# MIMXRT685S_cm33 register map
Vendor: nxp.com; File version: 1.0
CPU: CM33 r2p0, little endian, MPU, FPU, VTOR, 3 interrupt priority bits
Registers are 32-bit, read-write, reset 0x0 unless marked. A register's access mark holds for its fields unless they carry their own. Offsets are from the block's base; [hi:lo] are bit positions; lines under a group give offsets from that group; {n}, {i} and the like mark numbered series; 'fields as' and 'values as' point back to an identical list.

## OTFAD
Base 0x40134000; alternate view of FLEXSPI
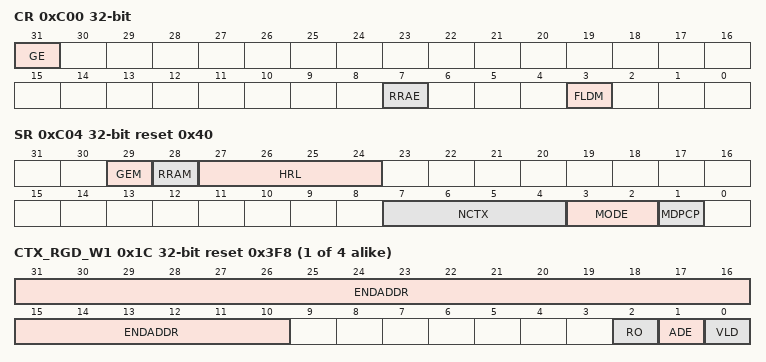
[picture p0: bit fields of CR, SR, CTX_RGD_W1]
0xC00 CR — Control Register
  [31] GE — Global OTFAD Enable
    0=OTFAD has decryption disabled. All data fetched by the FLEXSPI bypasses OTFAD processing.; 1=OTFAD has decryption enabled, and processes data fetched by the FLEXSPI as defined by the hardware configuration
  [7] RRAE — Restricted Register Access Enable
    0=Register access is fully enabled. The OTFAD programming model registers can be accessed "normally".; 1=Register access is restricted and only the CR, SR and optional MDPC registers can be accessed; others are treated as RAZ/WI
  [3] FLDM — Force Logically Disabled Mode
    0=No effect on the operating mode; 1=Force entry into LDM after a write with this data bit set. SR[MODE] signals the operating mode.
0xC04 SR ro reset 0x40 — Status Register
  [29] GEM — Global Enable Mode
    0=OTFAD is disabled. All data fetched by the FLEXSPI bypasses OTFAD processing.; 1=OTFAD is enabled, and processes data fetched by the FLEXSPI as defined by the hardware configuration
  [28] RRAM — Restricted Register Access Mode
    values as CR.RRAE
  [27:24] HRL — Hardware Revision Level
  [7:4] NCTX — Number of Contexts
  [3:2] MODE — Operating Mode
    0=Operating in Normal mode (NRM); 3=Operating in Logically Disabled Mode (LDM)
  [1] MDPCP — MDPC Present
{0xD00+0x40*i} CTX[{i}] (i=0..3) group
  {0x0+4j} CTX_KEY{j} (j=0..3) — AES Key Word
    [31:0] KEY — AES Key
  {0x10+4j} CTX_CTR{j} (j=0..1) — AES Counter Word
    [31:0] CTR — AES Counter
  0x18 CTX_RGD_W0 — AES Region Descriptor Word0
    [31:10] SRTADDR — Start Address
  0x1C CTX_RGD_W1 reset 0x3F8 — AES Region Descriptor Word1
    [31:10] ENDADDR — End Address
    [2] RO — Read-Only
      0=The context registers can be accessed normally (as defined by SR[RRAM]); 1=The context registers are read-only and accesses may be further restricted based on SR[RRAM]
    [1] ADE — AES Decryption Enable.
      0=Bypass the fetched data; 1=Perform the CTR-AES128 mode decryption on the fetched data
    [0] VLD — Valid
      0=Context is invalid; 1=Context is valid

## USBHSDCD — USBDCD
Base 0x4013B800
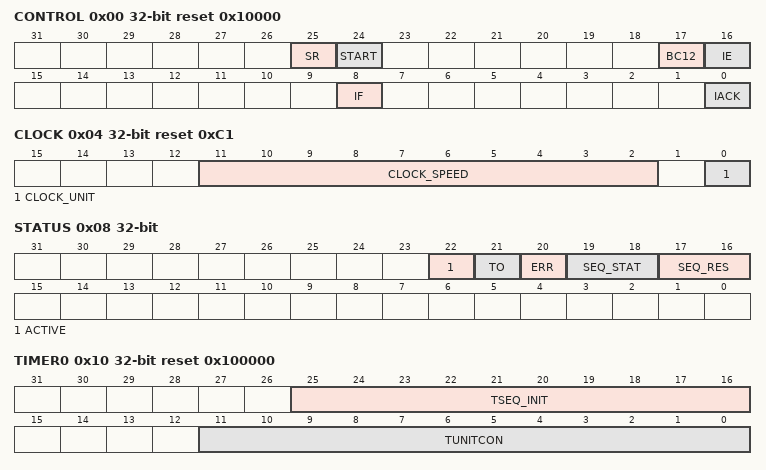
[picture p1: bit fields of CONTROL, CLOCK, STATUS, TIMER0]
0x00 CONTROL reset 0x10000
  [25] SR — Software Reset
    0=NO_RESET (Do not perform a software reset.); 1=SW_RESET (Perform a software reset.)
  [24] START — Start Change Detection Sequence
    0=NO_START (Do not start the sequence. Writes of this value have no effect.); 1=START (Initiate the charger detection sequence. If the sequence is already running, writes of this value have no effect.)
  [17] BC12
    0=BC11 (Compatible with BC1.1 (default)); 1=BC12 (Compatible with BC1.2)
  [16] IE — Interrupt Enable
    0=DIS_INT (Disable interrupts to the system.); 1=EN_INT (Enable interrupts to the system.)
  [8] IF ro — Interrupt Flag
    0=INT_PEND (No interrupt is pending.); 1=INT_NOPEND (An interrupt is pending.)
  [0] IACK — Interrupt Acknowledge
    0=INT_NOCLEAR (Do not clear the interrupt.); 1=INT_CLEAR (Clear the IF bit (interrupt flag).)
0x04 CLOCK reset 0xC1
  [11:2] CLOCK_SPEED — Numerical Value of Clock Speed in Binary
  [0] CLOCK_UNIT — Unit of Measurement Encoding for Clock Speed
    0=KHZ_CLK (kHz Speed (between 1 kHz and 1023 kHz)); 1=MHZ_CLK (MHz Speed (between 1 MHz and 1023 MHz))
0x08 STATUS ro
  [22] ACTIVE — Active Status Indicator
    0=SEQ_NOT_RUNNING (The sequence is not running.); 1=SEQ_RUNNING (The sequence is running.)
  [21] TO — Timeout Flag
    0=NO_TIMEOUT (The detection sequence has not been running for over 1 s.); 1=TIMEOUT (It has been over 1 s since the data pin contact was detected and debounced.)
  [20] ERR — Error Flag
    0=NO_SEQ_ERR (No sequence errors.); 1=SEQ_ERR (Error in the detection sequence. See the SEQ_STAT field to determine the phase in which the error occurred.)
  [19:18] SEQ_STAT — Charger Detection Sequence Status
    0=NO_DATA_PIN_CONN (The module is either not enabled, or the module is enabled but the data pins have not yet been detected.); 1=DATA_PIN_CONN (Data pin contact detection is complete.); 2=CP_DET_DONE (Charging port detection is complete.); 3=CT_DET_DONE (Charger type detection is complete.)
  [17:16] SEQ_RES — Charger Detection Sequence Results
    0=NO_RESULT (No results to report.); 1=CONN_SDP (Attached to an SDP. Must comply with USB 2.0 by drawing only 2.5 mA (max) until connected.); 2=CONN_CP (Attached to a charging port. The exact meaning depends on bit 18 (value 0: Attached to either a CDP or a DCP. The charger type detection has not completed. value 1: Attached to a CDP. The charger type detection has completed.)); 3=CONN_DCP (Attached to a DCP.)
0x0C SIGNAL_OVERRIDE
  [1:0] PS — Phase Selection
    0=NO_OVERRIDE (No overrides. Bit field must remain at this value during normal USB data communication to prevent unexpected conditions on USB_DP and USB_DM pins. (Default)); 2=PRI_DET_OVERRIDE (Enables VDP_SRC voltage source for the USB_DP pin and IDM_SINK current source for the USB_DM pin.)
0x10 TIMER0 reset 0x100000
  [25:16] TSEQ_INIT — Sequence Initiation Time
  [11:0] TUNITCON ro — Unit Connection Timer Elapse (in ms)
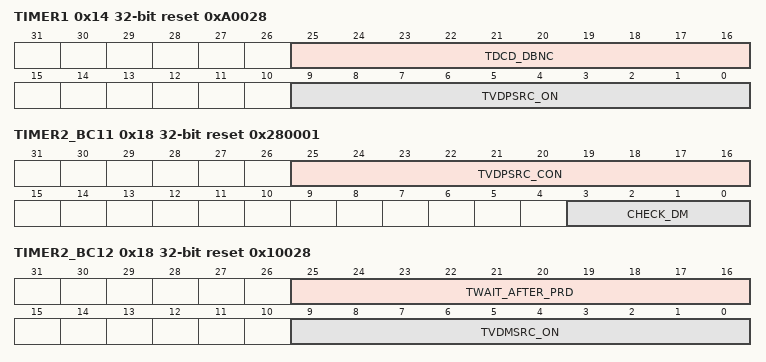
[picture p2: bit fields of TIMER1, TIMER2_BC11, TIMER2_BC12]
0x14 TIMER1 reset 0xA0028
  [25:16] TDCD_DBNC — Time Period to Debounce D+ Signal
  [9:0] TVDPSRC_ON — Time Period Comparator Enabled
0x18 TIMER2_BC11 reset 0x280001 (TIMER2 view)
  [25:16] TVDPSRC_CON — Time Period Before Enabling D+ Pullup
  [3:0] CHECK_DM — Time Before Check of D- Line
0x18 TIMER2_BC12 reset 0x10028 (TIMER2 view)
  [25:16] TWAIT_AFTER_PRD, [9:0] TVDMSRC_ON
